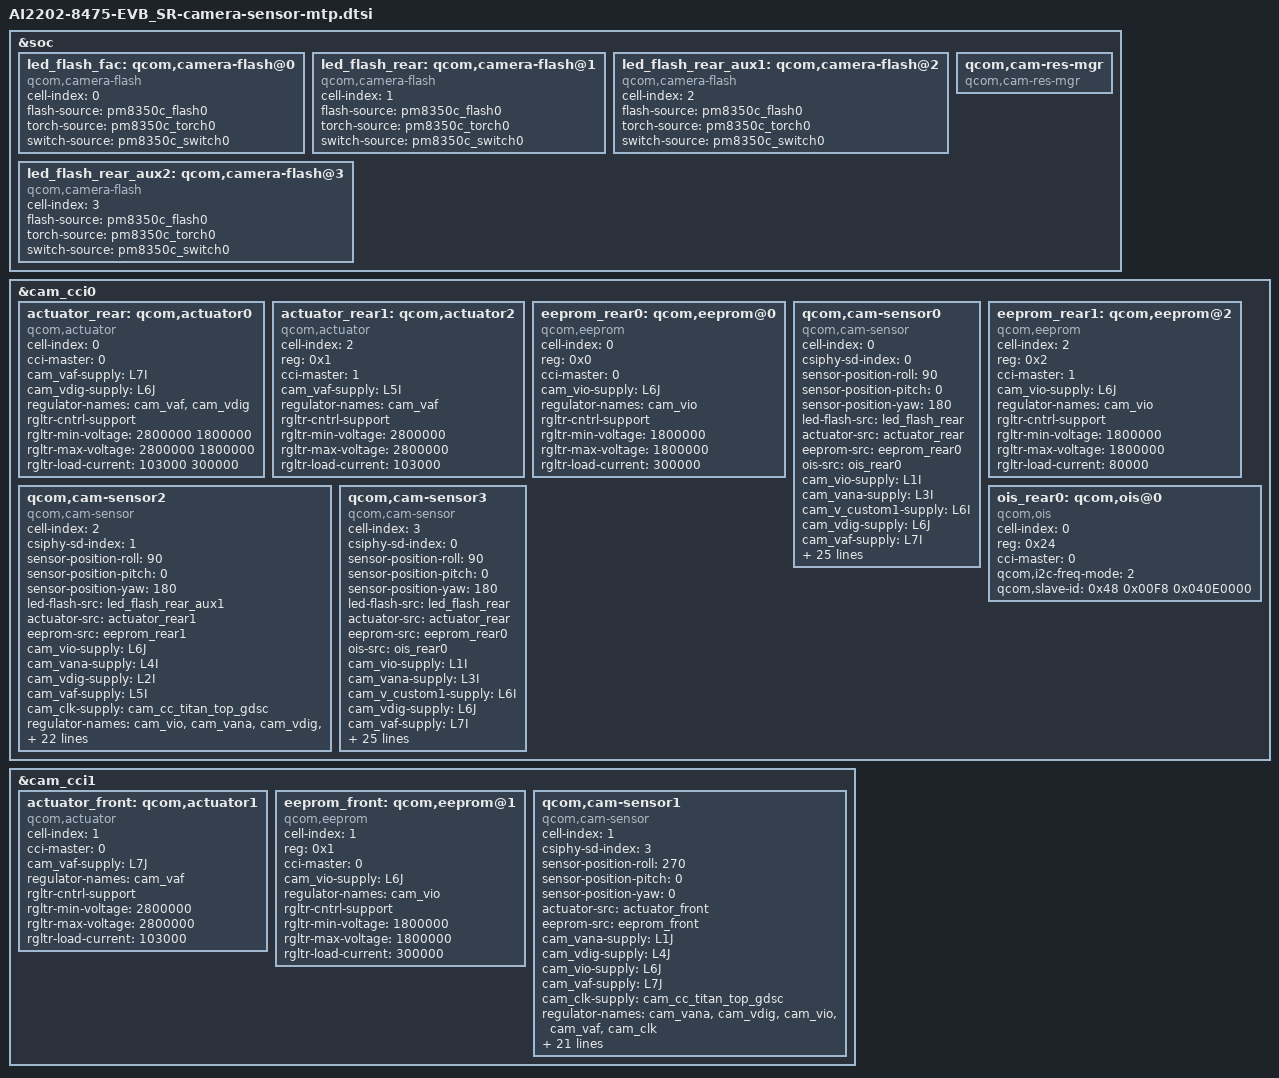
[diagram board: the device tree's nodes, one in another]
#include <dt-bindings/clock/qcom,camcc-waipio.h>

&soc {
	led_flash_fac: qcom,camera-flash@0 {
		cell-index = <0>;
		compatible = "qcom,camera-flash";
		flash-source = <&pm8350c_flash0>;
		torch-source = <&pm8350c_torch0>;
		switch-source = <&pm8350c_switch0>;
		status = "ok";
	};

	led_flash_rear: qcom,camera-flash@1 {
		cell-index = <1>;
		compatible = "qcom,camera-flash";
		flash-source = <&pm8350c_flash0>;
		torch-source = <&pm8350c_torch0>;
		switch-source = <&pm8350c_switch0>;
		status = "ok";
	};

	led_flash_rear_aux1: qcom,camera-flash@2 {
		cell-index = <2>;
		compatible = "qcom,camera-flash";
		flash-source = <&pm8350c_flash0>;
		torch-source = <&pm8350c_torch0>;
		switch-source = <&pm8350c_switch0>;
		status = "ok";
	};

	led_flash_rear_aux2: qcom,camera-flash@3 {
		cell-index = <3>;
		compatible = "qcom,camera-flash";
		flash-source = <&pm8350c_flash0>;
		torch-source = <&pm8350c_torch0>;
		switch-source = <&pm8350c_switch0>;
		status = "ok";
	};
	qcom,cam-res-mgr {
		compatible = "qcom,cam-res-mgr";
		status = "ok";
	};
};

&cam_cci0 {

	actuator_rear: qcom,actuator0 {
		cell-index = <0>;
		compatible = "qcom,actuator";
		cci-master = <0>;
		cam_vaf-supply = <&L7I>;
		cam_vdig-supply = <&L6J>;
		regulator-names = "cam_vaf", "cam_vdig";
		rgltr-cntrl-support;
		rgltr-min-voltage = <2800000 1800000>;
		rgltr-max-voltage = <2800000 1800000>;
		rgltr-load-current = <103000 300000>;
	};

	actuator_rear1: qcom,actuator2 {
		cell-index = <2>;
		reg = <0x1>;
		compatible = "qcom,actuator";
		cci-master = <1>;
		cam_vaf-supply = <&L5I>;
		regulator-names = "cam_vaf";
		rgltr-cntrl-support;
		rgltr-min-voltage = <2800000>;
		rgltr-max-voltage = <2800000>;
		rgltr-load-current = <103000>;
	};


	eeprom_rear0: qcom,eeprom@0 {
		cell-index = <0>;
		reg = <0x0>;
		cci-master = <0>;
		compatible = "qcom,eeprom";
		cam_vio-supply = <&L6J>;    //MCAM0_DOVDD_T_1P8
		regulator-names = "cam_vio";
		rgltr-cntrl-support;
		rgltr-min-voltage = <1800000>;
		rgltr-max-voltage = <1800000>;
		rgltr-load-current = <300000>;
		status = "ok";
	};

	//######## IMX686 / IMX766_12m #########
	qcom,cam-sensor0 {
		cell-index = <0>;
		csiphy-sd-index = <0>;
		compatible = "qcom,cam-sensor";
		sensor-position-roll = <90>;
		sensor-position-pitch = <0>;
		sensor-position-yaw = <180>;
		led-flash-src = <&led_flash_rear>;
		actuator-src = <&actuator_rear>;
		eeprom-src = <&eeprom_rear0>;
		ois-src = <&ois_rear0>;
		cam_vio-supply = <&L1I>;        //MCAM0_DVDD_T_1P1  VREG_L1I_1P1
		cam_vana-supply = <&L3I>;       //MCAM0_AVDD_T_2P8  VREG_L3I_2P8
		cam_v_custom1-supply = <&L6I>;  //MCAM0_AVDD_T_1P8  VREG_L6I_1P8
		cam_vdig-supply = <&L6J>;       //MCAM0_DOVDD_T_1P8 VREG_L6J_1P8
		cam_vaf-supply = <&L7I>;        //MVCM_2P8 VREG_L7I_2P8
		cam_v_custom2-supply = <&L5J>;      //VM 2.8 PM8010_1 LDO7 VM
		cam_clk-supply = <&cam_cc_titan_top_gdsc>;
		regulator-names = "cam_vio", "cam_vana", "cam_v_custom1", "cam_vdig", "cam_vaf","cam_v_custom2", "cam_clk";
		rgltr-cntrl-support;
		rgltr-min-voltage = <1000000 2800000 1800000 1800000 2800000 2800000 0>;
		rgltr-max-voltage = <1200000 2800000 1800000 1800000 2800000 2800000 0>;
		rgltr-load-current = <872000 80000 0 0 0 0 0>;
		gpio-no-mux = <0>;
		pinctrl-names = "cam_default", "cam_suspend";
		pinctrl-0 = <&cam_sensor_mclk0_active
			&cam_sensor_active_rst0>;
		pinctrl-1 = <&cam_sensor_mclk0_suspend
			&cam_sensor_suspend_rst0>;
		gpios = <&tlmm 100 0>,
			<&tlmm 25 0>;
		gpio-reset = <1>;
		gpio-req-tbl-num = <0 1>;
		gpio-req-tbl-flags = <1 0>;
		gpio-req-tbl-label = "CAMIF_MCLK0",
					"CAM_RESET0";
		cci-master = <0>;
		clocks = <&clock_camcc CAM_CC_MCLK0_CLK>;
		clock-names = "cam_clk";
		clock-cntl-level = "nominal";
		clock-rates = <19200000>;
		status = "ok";
	};

	eeprom_rear1: qcom,eeprom@2{
		cell-index = <2>;
		reg = <0x2>;
		cci-master = <1>;
		compatible = "qcom,eeprom";
		cam_vio-supply = <&L6J>;    //PM8008_2_LDO5_1P8
		regulator-names = "cam_vio";
		rgltr-cntrl-support;
		rgltr-min-voltage = <1800000>;
		rgltr-max-voltage = <1800000>;
		rgltr-load-current = <80000>;
		status = "ok";
	};

	//######## IMX363 #########
	qcom,cam-sensor2 {
		cell-index = <2>;
		compatible = "qcom,cam-sensor";
		csiphy-sd-index = <1>;
		sensor-position-roll = <90>;
		sensor-position-pitch = <0>;
		sensor-position-yaw = <180>;
		led-flash-src = <&led_flash_rear_aux1>;
		actuator-src = <&actuator_rear1>;
		eeprom-src = <&eeprom_rear1>;
		cam_vio-supply = <&L6J>;     //MCAM1_DOVDD_W_1P8   VREG_L6J_1P8
		cam_vana-supply = <&L4I>;    // L6I -> L4I
		cam_vdig-supply = <&L2I>;    //MCAM1_DVDD_W_1P2    VREG_L2I_1P2
		cam_vaf-supply = <&L5I>;
		cam_clk-supply = <&cam_cc_titan_top_gdsc>;
		regulator-names = "cam_vio", "cam_vana", "cam_vdig", "cam_vaf", "cam_clk";
		rgltr-cntrl-support;
		rgltr-min-voltage = <1800000 2704000 952000 2800000 0>;
		rgltr-max-voltage = <1800000 2896000 1144000 2800000 0>;
		rgltr-load-current = <20000 90000 550000 103000 0>;
		gpio-no-mux = <0>;
		pinctrl-names = "cam_default", "cam_suspend";
		pinctrl-0 = <&cam_sensor_mclk1_active
				 &cam_sensor_active_rst1>;
		pinctrl-1 = <&cam_sensor_mclk1_suspend
				 &cam_sensor_suspend_rst1>;
		gpios = <&tlmm 101 0>,
			<&tlmm 24 0>;
		gpio-reset = <1>;
		gpio-req-tbl-num = <0 1>;
		gpio-req-tbl-flags = <1 0>;
		gpio-req-tbl-label = "CAMIF_MCLK1",
					"CAM_RESET1";
		cci-master = <1>;
		clocks = <&clock_camcc CAM_CC_MCLK1_CLK>;
		clock-names = "cam_clk";
		clock-cntl-level = "nominal";
		clock-rates = <19200000>;
		status = "ok";
	};

	//######## IMX686 / IMX766 #########
	qcom,cam-sensor3 {
		cell-index = <3>;
		csiphy-sd-index = <0>;
		compatible = "qcom,cam-sensor";
		sensor-position-roll = <90>;
		sensor-position-pitch = <0>;
		sensor-position-yaw = <180>;
		led-flash-src = <&led_flash_rear>;
		actuator-src = <&actuator_rear>;
		eeprom-src = <&eeprom_rear0>;
		ois-src = <&ois_rear0>;
		cam_vio-supply = <&L1I>;        //MCAM0_DVDD_T_1P1  VREG_L1I_1P1
		cam_vana-supply = <&L3I>;       //MCAM0_AVDD_T_2P8  VREG_L3I_2P8
		cam_v_custom1-supply = <&L6I>;  //MCAM0_AVDD_T_1P8  VREG_L6I_1P8
		cam_vdig-supply = <&L6J>;       //MCAM0_DOVDD_T_1P8 VREG_L6J_1P8
		cam_vaf-supply = <&L7I>;        //MVCM_2P8 VREG_L7I_2P8
                cam_v_custom2-supply = <&L5J>;      //VM 2.8 PM8010_1 LDO7 VM
		cam_clk-supply = <&cam_cc_titan_top_gdsc>;
		regulator-names = "cam_vio", "cam_vana", "cam_v_custom1", "cam_vdig", "cam_vaf","cam_v_custom2", "cam_clk";
                rgltr-cntrl-support;
                rgltr-min-voltage = <1000000 2800000 1800000 1800000 2800000 2800000 0>;
                rgltr-max-voltage = <1200000 2800000 1800000 1800000 2800000 2800000 0>;
                rgltr-load-current = <872000 80000 0 0 0 0 0>;
		gpio-no-mux = <0>;
		pinctrl-names = "cam_default", "cam_suspend";
		pinctrl-0 = <&cam_sensor_mclk0_active
			&cam_sensor_active_rst0>;
		pinctrl-1 = <&cam_sensor_mclk0_suspend
			&cam_sensor_suspend_rst0>;
		gpios = <&tlmm 100 0>,
			<&tlmm 25 0>;
		gpio-reset = <1>;
		gpio-req-tbl-num = <0 1>;
		gpio-req-tbl-flags = <1 0>;
		gpio-req-tbl-label = "CAMIF_MCLK0",
					"CAM_RESET0";
		cci-master = <0>;
		clocks = <&clock_camcc CAM_CC_MCLK0_CLK>;
		clock-names = "cam_clk";
		clock-cntl-level = "nominal";
		clock-rates = <19200000>;
		status = "ok";
	};

	ois_rear0: qcom,ois@0 {
		cell-index = <0>;
		reg = <0x24>;
		compatible = "qcom,ois";
		cci-master = <0>;
		qcom,i2c-freq-mode = <2>;
		qcom,slave-id = <0x48 0x00F8 0x040E0000>;

		status = "ok";
	};
};

&cam_cci1 {
	actuator_front: qcom,actuator1 {
		cell-index = <1>;
		compatible = "qcom,actuator";
		cci-master = <0>;
		cam_vaf-supply = <&L7J>;
		regulator-names = "cam_vaf";
		rgltr-cntrl-support;
		rgltr-min-voltage = <2800000>;
		rgltr-max-voltage = <2800000>;
		rgltr-load-current = <103000>;
};

	eeprom_front: qcom,eeprom@1{
		cell-index = <1>;
		reg = <0x1>;
		cci-master = <0>;
		compatible = "qcom,eeprom";
		cam_vio-supply = <&L6J>;    //PM8008_LDO6_1P8
		regulator-names = "cam_vio";
		rgltr-cntrl-support;
		rgltr-min-voltage = <1800000>;
		rgltr-max-voltage = <1800000>;
		rgltr-load-current = <300000>;
		status = "ok";
};
	//######## Front imx663 #########
	qcom,cam-sensor1 {
		cell-index = <1>;
		compatible = "qcom,cam-sensor";
		csiphy-sd-index = <3>;
		sensor-position-roll = <270>;
		sensor-position-pitch = <0>;
		sensor-position-yaw = <0>;
		actuator-src = <&actuator_front>;
		eeprom-src = <&eeprom_front>;
		//led-flash-src = <&led_flash_rear1>;
		cam_vana-supply = <&L1J>;		        //VREG_L1J_1P1	  CAM_DVDD_F_1P1
		cam_vdig-supply = <&L4J>;		        //VREG_L4J_2P8	  CAM_AVDD_F_2P8
		cam_vio-supply = <&L6J>;		    	//VREG_L6J_1P8    CAM_DOVDD_F_1P8
		cam_vaf-supply = <&L7J>;
		cam_clk-supply = <&cam_cc_titan_top_gdsc>;
		regulator-names = "cam_vana", "cam_vdig","cam_vio","cam_vaf","cam_clk";
		rgltr-cntrl-support;
		rgltr-min-voltage = <1000000 2800000 1800000 2800000 0>;
		rgltr-max-voltage = <1200000 2800000 1800000 2800000 0>;
		rgltr-load-current = <872000 90000 20000 103000 0>;
		gpio-no-mux = <0>;
		pinctrl-names = "cam_default", "cam_suspend";
		pinctrl-0 = <&cam_sensor_mclk3_active
				&cam_sensor_active_rst3>;
		pinctrl-1 = <&cam_sensor_mclk3_suspend
				&cam_sensor_suspend_rst3>;
		gpios = <&tlmm 103 0>,
			<&tlmm 120 0>;
		gpio-reset = <1>;
		gpio-req-tbl-num = <0 1>;
		gpio-req-tbl-flags = <1 0>;
		gpio-req-tbl-label = "CAMIF_MCLK",
					"CAM_RESET";
		cci-master = <0>;
		status = "ok";
		clocks = <&clock_camcc CAM_CC_MCLK3_CLK>;
		clock-names = "cam_clk";
		clock-cntl-level = "nominal";
		clock-rates = <19200000>;
	};
};
